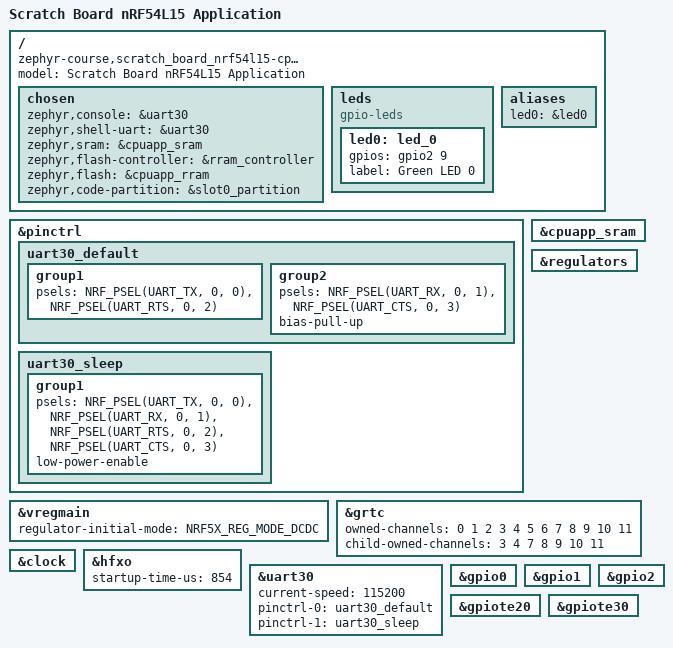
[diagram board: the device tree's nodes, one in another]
/*
 * SPDX-License-Identifier: Apache-2.0
 *
 * Minimal nRF54L15 DK board definition (from scratch).
 */

/dts-v1/;

#include <nordic/nrf54l15_cpuapp.dtsi>

/ {
	model = "Scratch Board nRF54L15 Application";
	compatible = "zephyr-course,scratch_board_nrf54l15-cpuapp";

	chosen {
		zephyr,console = &uart30;
		zephyr,shell-uart = &uart30;
		zephyr,sram = &cpuapp_sram;
		zephyr,flash-controller = &rram_controller;
		zephyr,flash = &cpuapp_rram;
		zephyr,code-partition = &slot0_partition;
	};

	leds {
		compatible = "gpio-leds";

		led0: led_0 {
			gpios = <&gpio2 9 GPIO_ACTIVE_HIGH>;
			label = "Green LED 0";
		};
	};

	aliases {
		led0 = &led0;
	};
};

&pinctrl {
	uart30_default: uart30_default {
		group1 {
			psels = <NRF_PSEL(UART_TX, 0, 0)>,
				<NRF_PSEL(UART_RTS, 0, 2)>;
		};

		group2 {
			psels = <NRF_PSEL(UART_RX, 0, 1)>,
				<NRF_PSEL(UART_CTS, 0, 3)>;
			bias-pull-up;
		};
	};

	uart30_sleep: uart30_sleep {
		group1 {
			psels = <NRF_PSEL(UART_TX, 0, 0)>,
				<NRF_PSEL(UART_RX, 0, 1)>,
				<NRF_PSEL(UART_RTS, 0, 2)>,
				<NRF_PSEL(UART_CTS, 0, 3)>;
			low-power-enable;
		};
	};
};

&cpuapp_sram {
	status = "okay";
};

&regulators {
	status = "okay";
};

&vregmain {
	status = "okay";
	regulator-initial-mode = <NRF5X_REG_MODE_DCDC>;
};

&grtc {
	owned-channels = <0 1 2 3 4 5 6 7 8 9 10 11>;
	child-owned-channels = <3 4 7 8 9 10 11>;
	status = "okay";
};

&clock {
	status = "okay";
};

&hfxo {
	startup-time-us = <854>;
};

&uart30 {
	status = "okay";
	current-speed = <115200>;
	pinctrl-0 = <&uart30_default>;
	pinctrl-1 = <&uart30_sleep>;
	pinctrl-names = "default", "sleep";
};

&gpio0 {
	status = "okay";
};

&gpio1 {
	status = "okay";
};

&gpio2 {
	status = "okay";
};

&gpiote20 {
	status = "okay";
};

&gpiote30 {
	status = "okay";
};

#include <nordic/nrf54l15_partition.dtsi>
